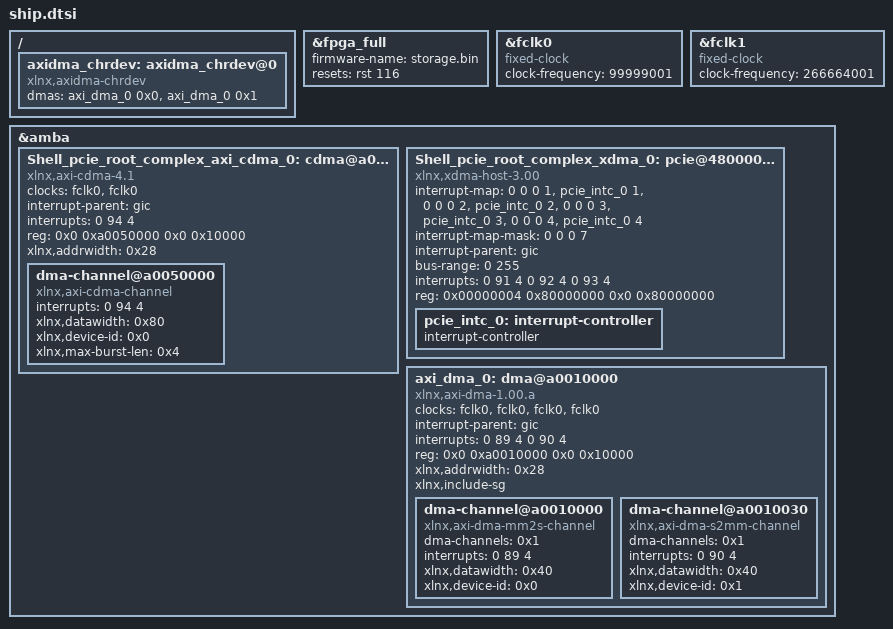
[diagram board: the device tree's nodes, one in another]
/*
 * CAUTION: This file is automatically generated by Xilinx.
 * Version: HSI 2018.3.1
 * Today is: Mon May  6 10:20:54 2019
 */


/dts-v1/;
/plugin/;
/ {
	fragment@0 {
		target = <&fpga_full>;
		overlay0: __overlay__ {
			#address-cells = <2>;
			#size-cells = <2>;
			firmware-name = "storage.bin";
			resets = <&rst 116>;
		};
	};
	fragment@1 {
		target = <&fclk0>;
		overlay1: __overlay__ {
			status = "okay";
			#clock-cells = <0>;
			clock-frequency = <99999001>;
			compatible = "fixed-clock";
		};
	};
	fragment@2 {
		target = <&fclk1>;
		overlay2: __overlay__ {
			status = "okay";
			#clock-cells = <0>;
			clock-frequency = <266664001>;
			compatible = "fixed-clock";
		};
	};
	fragment@3 {
		target = <&amba>;
		overlay3: __overlay__ {
			Shell_pcie_root_complex_axi_cdma_0: cdma@a0050000 {
				#dma-cells = <1>;
				clock-names = "m_axi_aclk", "s_axi_lite_aclk";
				clocks = <&fclk0>, <&fclk0>;
				compatible = "xlnx,axi-cdma-4.1", "xlnx,axi-cdma-1.00.a";
				interrupt-names = "cdma_introut";
				interrupt-parent = <&gic>;
				interrupts = <0 94 4>;
				reg = <0x0 0xa0050000 0x0 0x10000>;
				xlnx,addrwidth = <0x28>;
				dma-channel@a0050000 {
					compatible = "xlnx,axi-cdma-channel";
					interrupts = <0 94 4>;
					xlnx,datawidth = <0x80>;
					xlnx,device-id = <0x0>;
					xlnx,max-burst-len = <0x4>;
				};
			};
			Shell_pcie_root_complex_xdma_0: pcie@480000000 {
				#address-cells = <3>;
				#interrupt-cells = <1>;
				#size-cells = <2>;
				compatible = "xlnx,xdma-host-3.00";
				device_type = "pci";
				interrupt-map = <0 0 0 1 &pcie_intc_0 1>, <0 0 0 2 &pcie_intc_0 2>, <0 0 0 3 &pcie_intc_0 3>, <0 0 0 4 &pcie_intc_0 4>;
				//Try this:
				//interrupt-map = <0 0 0 1 &pcie_intc_0 1>, <0 0 0 2 &pcie_intc_0 2>, <0 0 0 3 &pcie_intc_0 3>;
				interrupt-map-mask = <0 0 0 7>;
				interrupt-names = "misc", "msi0", "msi1";
				interrupt-parent = <&gic>;
				bus-range = <0 255>; //addition
				interrupts = <0 91 4 0 92 4 0 93 4>;
				//ranges = <0x43000000 0x00000004 0x00000000 0x00000004 0x00000000 0x00000000 0x80000000>;
				//ranges = <0x02000000 0x00000000 0x00000000 0x00000000 0xA8000000 0x00000000 0x08000000>;
				ranges = <0x02000000 0x00000000 0x00000000 0x00000004 0x000000 0x00000000 0x80000000>;
				reg = <0x00000004 0x80000000 0x0 0x80000000>;
				pcie_intc_0: interrupt-controller {
					#address-cells = <0>;
					#interrupt-cells = <1>;
					interrupt-controller ;
				};
			};
			axi_dma_0: dma@a0010000 {
				#dma-cells = <1>;
				clock-names = "s_axi_lite_aclk", "m_axi_sg_aclk", "m_axi_mm2s_aclk", "m_axi_s2mm_aclk";
				clocks = <&fclk0>, <&fclk0>, <&fclk0>, <&fclk0>;
				compatible = "xlnx,axi-dma-1.00.a";
				interrupt-names = "mm2s_introut", "s2mm_introut";
				interrupt-parent = <&gic>;
				interrupts = <0 89 4 0 90 4>;
				reg = <0x0 0xa0010000 0x0 0x10000>;
				xlnx,addrwidth = <0x28>;
				xlnx,include-sg ;
				dma-channel@a0010000 {
					compatible = "xlnx,axi-dma-mm2s-channel";
					dma-channels = <0x1>;
					interrupts = <0 89 4>;
					xlnx,datawidth = <0x40>;
					xlnx,device-id = <0x0>;
				};
				dma-channel@a0010030 {
					compatible = "xlnx,axi-dma-s2mm-channel";
					dma-channels = <0x1>;
					interrupts = <0 90 4>;
					xlnx,datawidth = <0x40>;
					xlnx,device-id = <0x1>;
				};
			};
		};
	};
	fragment@4 {
		target-path = "/";
		overlay4: __overlay__ {
			axidma_chrdev: axidma_chrdev@0 {
				compatible = "xlnx,axidma-chrdev";
				dmas = <&axi_dma_0 0x0 &axi_dma_0 0x1>;
				dma-names = "tx_channel", "rx_channel";
			};
		};
	};
};
